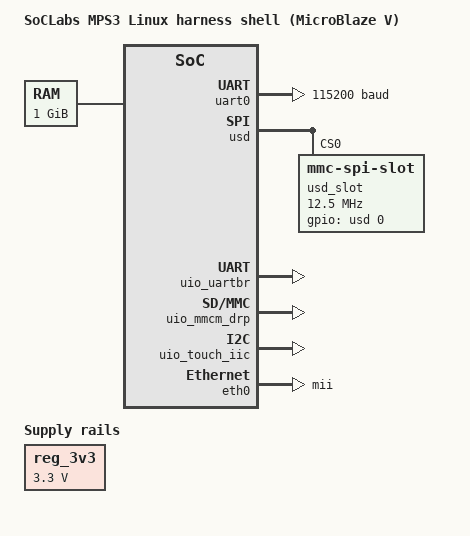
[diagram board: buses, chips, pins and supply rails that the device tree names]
/dts-v1/;

/*
 * shell_linux.dts — GENERATED by tools/gen_dts.py. DO NOT EDIT BY HAND.
 * Regenerate: python3 tools/gen_dts.py     Gate: python3 tools/dts_gates.py
 *
 * The MPS3 static shell with the MicroBlaze V CPU seam (SHELL_CPU=mbv):
 *   contract blocks  fpga/shell/bd/shell_bd.tcl via gen_regmap.derive()
 *   CPU-side cells   fpga/shell/bd/shell_bd.tcl + fpga/shell/bd/cpu_mbv.tcl
 *   DDR / LMB        fpga/shell/bd/cpu_mbv.tcl
 *   owners           fpga/shell/generated/regmap_mbv.json
 *   gated additions  SHELL_TOUCH=1
 *
 * OWNERSHIP (LINUX_HARNESS_PLAN §3): a kernel-owned block has its driver
 * and no generic-uio; a harnessd-owned block has ONE node whose only
 * compatible is generic-uio (HARNESSD_CONTRACT §3). Never both.
 *
 * BOOT MAP (OpenSBI 1.6 fw_payload / fw_jump, rv32): OpenSBI @0x8000_0000,
 * Image @0x8040_0000 with the rootfs EMBEDDED (no linux,initrd-* to
 * stamp), this DTB @0x8220_0000, padded by dtc -p 4096 for OpenSBI's
 * in-place fixups (IMAGE_CONTRACT §1.2).
 */

/ {
	#address-cells = <1>;
	#size-cells = <1>;
	model = "SoCLabs MPS3 Linux harness shell (MicroBlaze V)";
	compatible = "soclabs,mps3-harness-shell";

	chosen {
		stdout-path = "serial0:115200n8";
		/* uio_pdrv_genirq.of_id=generic-uio is LOAD-BEARING: it binds every
		 * harnessd-owned node (the driver's of_id table is empty otherwise). */
		bootargs = "console=ttyUL0,115200 earlycon=uartlite,mmio32,0x40600000 uio_pdrv_genirq.of_id=generic-uio";
	};

	aliases {
		serial0 = &uart0;
		ethernet0 = &eth0;
		spi0 = &usd;
	};

	cpus {
		#address-cells = <1>;
		#size-cells = <0>;
		timebase-frequency = <100000000>;

		/* MicroBlaze V, RV32IMAC + Sv32. The BD read-back-asserts
		 * C_USE_COUNTERS=1 (rdtime) and C_INTERRUPT_WAKEUP=1 and keeps
		 * C_USE_SSTC=1 latent: "sstc" is deliberately NOT listed (errata
		 * E1/E2, see the timer node). No zicbom, no zbc. */
		cpu0: cpu@0 {
			device_type = "cpu";
			compatible = "amd,mbv32", "riscv";
			reg = <0>;
			status = "okay";
			clock-frequency = <100000000>;
			mmu-type = "riscv,sv32";
			riscv,isa-base = "rv32i";
			riscv,isa-extensions = "i", "m", "a", "c", "zicsr", "zifencei", "zicntr", "zba", "zbb", "zbs";
			riscv,isa = "rv32imac_zicsr_zifencei_zba_zbb_zbs";

			cpu_intc: interrupt-controller {
				compatible = "riscv,cpu-intc";
				interrupt-controller;
				#address-cells = <0>;   /* dtc >= 1.6.1 interrupt_provider */
				#interrupt-cells = <1>;
			};
		};
	};

	/* DDR4 only. The LMB (0x0, 128 KiB) is NOT memory to Linux. */
	memory@80000000 {
		device_type = "memory";
		reg = <0x80000000 0x40000000>;
	};

	reserved-memory {
		#address-cells = <1>;
		#size-cells = <1>;
		ranges;

		/* ramoops/pstore, top MiB of DDR: survives a CPU-only warm reset
		 * (S15pstore). The JTAG-readable diag mailbox is the LMB tail. */
		ramoops@bff00000 {
			compatible = "ramoops";
			reg = <0xbff00000 0x100000>;
			record-size = <0x20000>;
			console-size = <0x40000>;
			pmsg-size = <0x20000>;
		};
	};

	/* shell_clk = clk_wiz_shell/clk_out1: no AXI interface, so a fixed
	 * clock is the honest model. */
	clk100: clock-100000000 {
		compatible = "fixed-clock";
		#clock-cells = <0>;
		clock-frequency = <100000000>;
		clock-output-names = "shell_clk";
	};

	/* LAN9220 supplies: hard-wired 3V3 on the MPS3. */
	reg_3v3: regulator-3v3 {
		compatible = "regulator-fixed";
		regulator-name = "board-3v3";
		regulator-min-microvolt = <3300000>;
		regulator-max-microvolt = <3300000>;
		regulator-always-on;
	};

	soc {
		compatible = "simple-bus";
		#address-cells = <1>;
		#size-cells = <1>;
		ranges;

		/* LMB_TAIL — fpga/shell/bd/cpu_mbv.tcl (local_ram, last 4 KiB page). harnessd-owned. */
		uio_lmb_tail: lmb-tail@1f000 {
			compatible = "generic-uio";
			reg = <0x1f000 0x1000>;
			linux,uio-name = "lmb-tail";
		};

		/* Console uartlite — fpga/shell/bd/shell_bd.tcl (axi_uartlite_0). THE console (FT4232 lane 2, the
		 * tty_02 share on the hub). Stock IRQ-driven; 115200 fixed in HW. */
		uart0: serial@40600000 {
			compatible = "xlnx,xps-uartlite-1.00.a";
			reg = <0x40600000 0x10000>;
			interrupt-parent = <&axi_intc>;
			interrupts = <2 4>;
			clocks = <&clk100>;
			clock-names = "s_axi_aclk";
			current-speed = <115200>;
			xlnx,data-bits = <8>;
			xlnx,use-parity = <0>;
		};

		/* AXI INTC — fpga/shell/bd/shell_bd.tcl (axi_intc_0). Chained under the hart's local intc at hwirq
		 * 9 (S-mode external). kind-of-intr 0 = every input LEVEL (the BD pins
		 * and asserts C_KIND_OF_INTR=0); irq-xilinx-intc picks its irq_chip off
		 * this word, and the 0003 timer / 0004 uartlite ISRs rely on LEVEL. */
		axi_intc: interrupt-controller@41200000 {
			compatible = "xlnx,xps-intc-1.00.a";
			reg = <0x41200000 0x10000>;
			interrupt-controller;
			#address-cells = <0>;      /* dtc >= 1.6.1 interrupt_provider */
			#interrupt-cells = <2>;
			xlnx,kind-of-intr = <0x0>;
			xlnx,num-intr-inputs = <5>;
			interrupt-parent = <&cpu_intc>;
			interrupts = <9>;
		};

		/* AXI timer — fpga/shell/bd/shell_bd.tcl (axi_timer_0). THE KERNEL TICK (MBV errata E1 Sstc dead,
		 * E2 STIP stuck): "soclabs,mbv-timer" binds the patch-0003 clockevent
		 * (channel 0 on SEIP through the INTC); patch 0007 routes udelay onto its
		 * free-running counter because rdtime freezes in a busy-spin.
		 * clock-frequency is REQUIRED by that driver. Never claim
		 * "xlnx,axi-timer-2.0" (it binds pwm-xilinx). Fixed-IP re-enable: restore
		 * "sstc" on the cpu AND drop the soclabs prefix, in one commit. */
		axi_timer: timer@41c00000 {
			compatible = "soclabs,mbv-timer", "xlnx,xps-timer-1.00.a";
			reg = <0x41c00000 0x10000>;
			interrupt-parent = <&axi_intc>;
			interrupts = <1 4>;
			clocks = <&clk100>;
			clock-names = "s_axi_aclk";
			clock-frequency = <100000000>;
			xlnx,count-width = <32>;
			xlnx,one-timer-only = <0>;
		};

		/* CLKRST — fpga/shell/bd/shell_bd.tcl (dut_clkrst_0). harnessd-owned. */
		uio_clkrst: clkrst@44a00000 {
			compatible = "generic-uio";
			reg = <0x44a00000 0x10000>;
			linux,uio-name = "clkrst";
		};

		/* DFXCTL — fpga/shell/bd/shell_bd.tcl (dfx_ctl_0). harnessd-owned. */
		uio_dfxctl: dfxctl@44a10000 {
			compatible = "generic-uio";
			reg = <0x44a10000 0x10000>;
			linux,uio-name = "dfxctl";
		};

		/* HWICAP — fpga/shell/bd/shell_bd.tcl (axi_hwicap_0). harnessd-owned. */
		uio_hwicap: hwicap@44a20000 {
			compatible = "generic-uio";
			reg = <0x44a20000 0x10000>;
			linux,uio-name = "hwicap";
		};

		/* VPHY — fpga/shell/bd/shell_bd.tcl (eth_mac_test_subsystem_0). harnessd-owned. */
		uio_vphy: vphy@44a30000 {
			compatible = "generic-uio";
			reg = <0x44a30000 0x1000>;
			linux,uio-name = "vphy";
		};

		/* User microSD — fpga/shell/bd/shell_bd.tcl (usd_spi_0): D13's usd_spi (SPI mode, runtime divider,
		 * debounced card detect, hardware pad gate). Kernel-owned: the spi-usd
		 * controller (br2_external package mps3-spi-usd) + the stock mmc_spi slot
		 * -> /dev/mmcblk0. The controller is also a 1-line GPIO chip whose line 0
		 * is STATUS.CD_PRESENT, so the MMC core polls one register a second
		 * instead of clocking CMD0 into an empty socket: no card => no SPI
		 * traffic, no delay, no error (D13 hard rule 1). 400 kHz identification
		 * is the MMC core's f_min; 12.5 MHz is D13's default data rate. */
		usd: spi@44a40000 {
			compatible = "soclabs,usd-spi-1.0";
			reg = <0x44a40000 0x10000>;
			clocks = <&clk100>;
			#address-cells = <1>;
			#size-cells = <0>;
			gpio-controller;
			#gpio-cells = <2>;

			usd_slot: mmc@0 {
				compatible = "mmc-spi-slot";
				reg = <0>;
				spi-max-frequency = <12500000>;
				voltage-ranges = <3300 3300>;
				/* mmc-spi-slot's CD is index 0 of the LEGACY "gpios" property
				 * (mmc_spi.c: mmc_gpiod_request_cd(mmc, NULL, 0, ...)); a cd-gpios
				 * here would be ignored and the core would poll CMD0 instead. */
				gpios = <&usd 0 0>;	/* line 0 = STATUS.CD_PRESENT, active high */
			};
		};

		/* TELEM — fpga/shell/bd/shell_bd.tcl (telem_0). harnessd-owned. */
		uio_telem: telem@44a50000 {
			compatible = "generic-uio";
			reg = <0x44a50000 0x10000>;
			linux,uio-name = "telem";
		};

		/* GENCHK — fpga/shell/bd/shell_bd.tcl (eth_mac_test_subsystem_0). harnessd-owned. */
		uio_genchk: genchk@44a60000 {
			compatible = "generic-uio";
			reg = <0x44a60000 0x1000>;
			linux,uio-name = "genchk";
		};

		/* JTAGBB — fpga/shell/bd/shell_bd.tcl (jtag_bb_0). harnessd-owned. */
		uio_jtag_bb: jtag-bb@44a70000 {
			compatible = "generic-uio";
			reg = <0x44a70000 0x10000>;
			linux,uio-name = "jtag-bb";
		};

		/* DBGBR — fpga/shell/bd/shell_bd.tcl (debug_bridge_0). harnessd-owned. */
		uio_dbgbr: dbgbr@44a80000 {
			compatible = "generic-uio";
			reg = <0x44a80000 0x10000>;
			linux,uio-name = "dbgbr";
		};

		/* UARTBR — fpga/shell/bd/shell_bd.tcl (uart_bridge_0). harnessd-owned. */
		uio_uartbr: uartbr@44a90000 {
			compatible = "generic-uio";
			reg = <0x44a90000 0x10000>;
			linux,uio-name = "uartbr";
		};

		/* GPIO — fpga/shell/bd/shell_bd.tcl (board_gpio_0). harnessd-owned. */
		uio_gpio: gpio@44aa0000 {
			compatible = "generic-uio";
			reg = <0x44aa0000 0x10000>;
			linux,uio-name = "gpio";
		};

		/* MMCM_DRP — fpga/shell/bd/shell_bd.tcl (clk_wiz_dut). harnessd-owned. */
		uio_mmcm_drp: mmcm-drp@44ab0000 {
			compatible = "generic-uio";
			reg = <0x44ab0000 0x10000>;
			linux,uio-name = "mmcm-drp";
		};

		/* CLCD — fpga/shell/bd/shell_bd.tcl (clcd_0). harnessd-owned. */
		uio_clcd: clcd@44ac0000 {
			compatible = "generic-uio";
			reg = <0x44ac0000 0x10000>;
			linux,uio-name = "clcd";
		};

		/* CLCDKVM — fpga/shell/bd/shell_bd.tcl (clcd_kvm_0). harnessd-owned. */
		uio_clcd_kvm: clcd-kvm@44ad0000 {
			compatible = "generic-uio";
			reg = <0x44ad0000 0x10000>;
			linux,uio-name = "clcd-kvm";
		};

		/* TOUCH — fpga/shell/bd/touch_iic_add.tcl (touch_iic_0). harnessd-owned. GATED: built only with SHELL_TOUCH=1 (the MBV mint sets it). */
		uio_touch_iic: touch-iic@44ae0000 {
			compatible = "generic-uio";
			reg = <0x44ae0000 0x10000>;
			linux,uio-name = "touch-iic";
		};

		/* DUTEGR — fpga/shell/bd/shell_bd.tcl (dut_egress_0). harnessd-owned. */
		uio_dutegr: dutegr@44b20000 {
			compatible = "generic-uio";
			reg = <0x44b20000 0x10000>;
			linux,uio-name = "dutegr";
		};

		/* USRACC — fpga/shell/bd/shell_bd.tcl (usr_access_rd_0). harnessd-owned. */
		uio_usracc: usracc@44b30000 {
			compatible = "generic-uio";
			reg = <0x44b30000 0x10000>;
			linux,uio-name = "usracc";
		};

		/* WDOG — fpga/shell/bd/shell_bd.tcl (axi_timebase_wdt_0). harnessd-owned. */
		uio_wdog: wdog@44b40000 {
			compatible = "generic-uio";
			reg = <0x44b40000 0x10000>;
			linux,uio-name = "wdog";
		};

		/* LAN9220 behind the AXI EMC — fpga/shell/bd/shell_bd.tcl (axi_emc_0) (16 MiB decode; the chip
		 * aliases every 256 B).
		 * reg-io-width = <4>: the EMC assembles two 16-bit cycles into ONE 32-bit
		 *   AXI beat, exactly as the bare-metal driver reads it. <2> popped the RX
		 *   data FIFO twice per word and overran skbs into slab (the July 57 s
		 *   hrtimer oops). Do not change it.
		 * ETH_INT POLARITY TRIPLE (SHELL_CONTRACT §4; silicon 2026-07-19) — the
		 *   three ship together or eth0 up livelocks the kernel:
		 *   (1) NO smsc,irq-active-high / smsc,irq-push-pull here,
		 *   (2) PULLTYPE PULLUP on ETH_INT,
		 *   (3) the INTC sees ~ETH_INT (shell_top, MPS3_SHELL_CPU_MBV).
		 *   tools/dts_gates.py checks all three. */
		eth0: ethernet@c0000000 {
			compatible = "smsc,lan9220", "smsc,lan9115";
			reg = <0xc0000000 0x10000>;
			interrupt-parent = <&axi_intc>;
			interrupts = <3 4>;
			reg-io-width = <4>;
			smsc,force-internal-phy;
			local-mac-address = [02 00 00 4D 50 53];
			vdd33a-supply = <&reg_3v3>;
			vddvario-supply = <&reg_3v3>;
			phy-mode = "mii";
		};
	};
};
